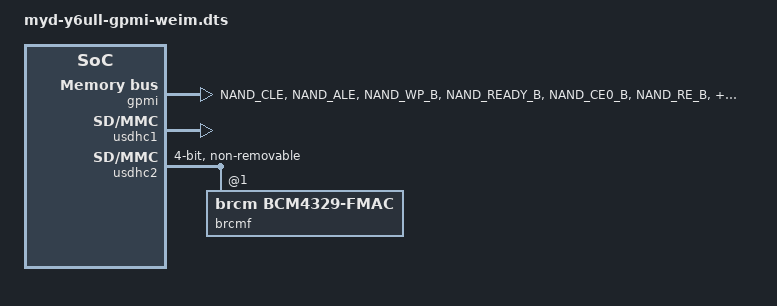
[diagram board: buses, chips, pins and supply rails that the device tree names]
/*
 * Copyright (C) 2016 Freescale Semiconductor, Inc.
 * Copyright (C) myir alex 
 * This program is free software; you can redistribute it and/or modify
 * it under the terms of the GNU General Public License version 2 as
 * published by the Free Software Foundation.
 */

#include "myb-imx6ull-14x14-base.dts"

&gpmi {
	pinctrl-names = "default";
	pinctrl-0 = <&pinctrl_gpmi_nand_1>;
	status = "okay";
	nand-on-flash-bbt;
};

&iomuxc {
		pinctrl_gpmi_nand_1: gpmi-nand-1 {
			fsl,pins = <
				MX6UL_PAD_NAND_CLE__RAWNAND_CLE         0xb0b1
				MX6UL_PAD_NAND_ALE__RAWNAND_ALE         0xb0b1
				MX6UL_PAD_NAND_WP_B__RAWNAND_WP_B       0xb0b1
				MX6UL_PAD_NAND_READY_B__RAWNAND_READY_B 0xb000
				MX6UL_PAD_NAND_CE0_B__RAWNAND_CE0_B     0xb0b1
				MX6UL_PAD_NAND_RE_B__RAWNAND_RE_B       0xb0b1
				MX6UL_PAD_NAND_WE_B__RAWNAND_WE_B       0xb0b1
				MX6UL_PAD_NAND_DATA00__RAWNAND_DATA00   0xb0b1
				MX6UL_PAD_NAND_DATA01__RAWNAND_DATA01   0xb0b1
				MX6UL_PAD_NAND_DATA02__RAWNAND_DATA02   0xb0b1
				MX6UL_PAD_NAND_DATA03__RAWNAND_DATA03   0xb0b1
				MX6UL_PAD_NAND_DATA04__RAWNAND_DATA04   0xb0b1
				MX6UL_PAD_NAND_DATA05__RAWNAND_DATA05   0xb0b1
				MX6UL_PAD_NAND_DATA06__RAWNAND_DATA06   0xb0b1
				MX6UL_PAD_NAND_DATA07__RAWNAND_DATA07   0xb0b1
			>;
		};
};

&usdhc1 {
	status = "okay";
};

&usdhc2 {
    #address-cells = <1>;
    #size-cells = <0>;
    pinctrl-names = "default";
    max-frequency = <50000000>;
    pinctrl-0 = <&pinctrl_usdhc2_alt &pinctrl_wifi>;
    bus-width = <4>;
    no-1-8-v;   /* force 3.3V VIO */
    non-removable;
    pm-ignore-notify;
    cap-power-off-card;
//    /delete-property/ wakeup-source;
    status = "okay";

    brcmf: bcrmf@1 {
        reg = <1>;
        compatible = "brcm,bcm4329-fmac";
    };
};

